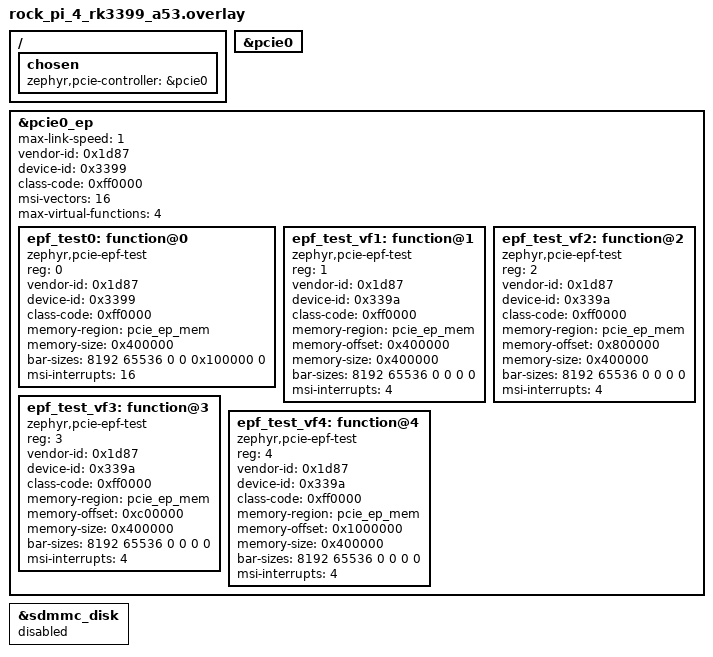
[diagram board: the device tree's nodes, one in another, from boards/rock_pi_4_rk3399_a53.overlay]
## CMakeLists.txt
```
# SPDX-License-Identifier: Apache-2.0

cmake_minimum_required(VERSION 3.20.0)
find_package(Zephyr REQUIRED HINTS $ENV{ZEPHYR_BASE})
project(rk3399_pcie_shell)

target_sources(app PRIVATE src/main.c)
target_sources_ifdef(CONFIG_SAMPLE_INIT_TRACE app PRIVATE src/inittrace.c)
```

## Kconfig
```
# SPDX-License-Identifier: Apache-2.0

config SAMPLE_INIT_TRACE
	bool "Print a marker between init priority bands"
	help
	  printk "init: <level> <priority>" at PRE_KERNEL_2 0 and at a row of
	  POST_KERNEL priorities, so the last marker on the console tells
	  between which driver priorities a boot hangs. Use with
	  -DEXTRA_CONF_FILE=debug.conf (immediate logging).

source "Kconfig.zephyr"
```

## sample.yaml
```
sample:
  name: RK3399 PCIe shell (root complex / endpoint)
tests:
  sample.boards.rockchip.rk3399.pcie_shell:
    platform_allow:
      - rock_pi_4/rk3399/a53
      - rock_pi_4/rk3399/a53/smp
    tags: pcie
    build_only: true
```

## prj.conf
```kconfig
CONFIG_GPIO=y
CONFIG_LOG=y
CONFIG_SHELL=y
CONFIG_KERNEL_SHELL=y
CONFIG_DEVMEM_SHELL=y
CONFIG_REBOOT=y
CONFIG_SHELL_STACK_SIZE=8192

# root complex
CONFIG_PCIE=y
CONFIG_PCIE_CONTROLLER=y
# endpoint
CONFIG_PCIE_ENDPOINT=y
CONFIG_PCIE_EP_LOG_LEVEL_INF=y
CONFIG_CRC=y
CONFIG_TEST_RANDOM_GENERATOR=y

# config space 32 MiB + outbound 32 MiB + BAR carveout, mapped at run time
CONFIG_KERNEL_VM_SIZE=0x10000000
CONFIG_MAX_XLAT_TABLES=64

# eMMC: boot medium and storage (FAT from 16 MiB, mounted at /EMMC: before
# the PCIe role is read); the micro SD slot
# is left to the JTAG breakout: host only, no SD card disk
CONFIG_SDHC=y
CONFIG_SDHC_INIT_PRIORITY=70
CONFIG_DISK_ACCESS=y
CONFIG_MMC_STACK=y
CONFIG_DISK_DRIVER_MMC=y
CONFIG_FILE_SYSTEM=y
# FAT registered before the eMMC mount (76): default 99 is too late
CONFIG_FILE_SYSTEM_INIT_PRIORITY=74
# the disk drivers on top of the SDHC hosts too (default 90)
CONFIG_SD_INIT_PRIORITY=72
CONFIG_FAT_FILESYSTEM_ELM=y
CONFIG_FS_FATFS_LFN=y
# a blank eMMC stays blank: mkfs over the whole disk would cover the boot area
CONFIG_FS_FATFS_MOUNT_MKFS=n
CONFIG_FILE_SYSTEM_SHELL=y
CONFIG_SETTINGS=y
CONFIG_SETTINGS_FILE=y
CONFIG_SETTINGS_FILE_PATH="/EMMC:/settings"
CONFIG_PCIE_ROLE_SETTINGS=y
CONFIG_MAIN_STACK_SIZE=8192

# SPI flash (4A+/4B+/4C): not used for booting; an old image there would
# win over the eMMC (BootROM order), "flash erase" clears it
CONFIG_SPI=y
CONFIG_FLASH=y
CONFIG_FLASH_SHELL=y

# "fwupdate ymodem" over the shell UART (tio ctrl-t y): <img>-rock_pi_4-spi.bin
# into the SPI NOR boot_partition, or on a board without SPI NOR
# <img>-rock_pi_4-boot.bin into the eMMC boot area
CONFIG_FLASH_MAP=y
CONFIG_FWUPDATE=y
CONFIG_FWUPDATE_BOOT_DISK=y

# SR-IOV strap: the core shows its SR-IOV capability (VFs not driven yet)
CONFIG_PCIE_EPC_RK3399_SRIOV=y
```

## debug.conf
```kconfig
# boot debugging: markers between init priorities, logs printed at once
CONFIG_SAMPLE_INIT_TRACE=y
CONFIG_EARLY_CONSOLE=y
CONFIG_LOG_MODE_IMMEDIATE=y
CONFIG_SDHC_LOG_LEVEL_DBG=y
CONFIG_SD_LOG_LEVEL_DBG=y
CONFIG_PCIE_EP_LOG_LEVEL_DBG=y
CONFIG_SPI_LOG_LEVEL_DBG=y
# printk and logs straight to the UART, not through the shell log backend
# (that one only prints once the shell thread runs)
CONFIG_LOG_PRINTK=n
CONFIG_SHELL_LOG_BACKEND=n
CONFIG_LOG_BACKEND_UART=y
```

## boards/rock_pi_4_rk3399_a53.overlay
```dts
/*
 * Copyright (c) 2026 Jiri Kastner
 * SPDX-License-Identifier: Apache-2.0
 *
 * Both roles of the one controller; CONFIG_PCIE_ROLE picks at boot.
 */

/ {
	chosen {
		zephyr,pcie-controller = &pcie0;
	};
};

&pcie0 {
	status = "okay";
};

&pcie0_ep {
	/* Gen2 over the crossover cable drops the data link every few hundred
	 * ms, and every drop resets the configuration space (BARs, VFs) */
	max-link-speed = <1>;
	vendor-id = <0x1d87>;
	device-id = <0x3399>;
	class-code = <0xff0000>;
	msi-vectors = <16>;
	status = "okay";

	epf_test0: function@0 {
		compatible = "zephyr,pcie-epf-test";
		reg = <0>;
		vendor-id = <0x1d87>;
		device-id = <0x3399>;
		class-code = <0xff0000>;
		memory-region = <&pcie_ep_mem>;
		memory-size = <0x400000>;
		/* BAR0 registers, 64-bit BARs need even numbers: 32-bit here */
		bar-sizes = <8192 65536 0 0 0x100000 0>;
		msi-interrupts = <16>;
	};
};

/* SD slot host kept for its JTAG handling (force_jtag), no card disk */
&sdmmc_disk {
	status = "disabled";
};

/*
 * SR-IOV: 4 VFs (routing functions 1..4), each a pcie_epf_test with its own
 * 4 MiB of the carveout. The VF BAR layout is shared, so bar-sizes match;
 * BAR4 is left out so 4 VFs fit a 2 MiB bridge window next to the PF.
 * Host: echo 4 > /sys/bus/pci/devices/<bdf>/sriov_numvfs
 */
&pcie0_ep {
	max-virtual-functions = <4>;

	epf_test_vf1: function@1 {
		compatible = "zephyr,pcie-epf-test";
		reg = <1>;
		vendor-id = <0x1d87>;
		device-id = <0x339a>;
		class-code = <0xff0000>;
		memory-region = <&pcie_ep_mem>;
		memory-offset = <0x400000>;
		memory-size = <0x400000>;
		bar-sizes = <8192 65536 0 0 0 0>;
		msi-interrupts = <4>;
	};

	epf_test_vf2: function@2 {
		compatible = "zephyr,pcie-epf-test";
		reg = <2>;
		vendor-id = <0x1d87>;
		device-id = <0x339a>;
		class-code = <0xff0000>;
		memory-region = <&pcie_ep_mem>;
		memory-offset = <0x800000>;
		memory-size = <0x400000>;
		bar-sizes = <8192 65536 0 0 0 0>;
		msi-interrupts = <4>;
	};

	epf_test_vf3: function@3 {
		compatible = "zephyr,pcie-epf-test";
		reg = <3>;
		vendor-id = <0x1d87>;
		device-id = <0x339a>;
		class-code = <0xff0000>;
		memory-region = <&pcie_ep_mem>;
		memory-offset = <0xc00000>;
		memory-size = <0x400000>;
		bar-sizes = <8192 65536 0 0 0 0>;
		msi-interrupts = <4>;
	};

	epf_test_vf4: function@4 {
		compatible = "zephyr,pcie-epf-test";
		reg = <4>;
		vendor-id = <0x1d87>;
		device-id = <0x339a>;
		class-code = <0xff0000>;
		memory-region = <&pcie_ep_mem>;
		memory-offset = <0x1000000>;
		memory-size = <0x400000>;
		bar-sizes = <8192 65536 0 0 0 0>;
		msi-interrupts = <4>;
	};
};
```

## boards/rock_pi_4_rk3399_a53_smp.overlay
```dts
/*
 * Copyright (c) 2026 Jiri Kastner
 * SPDX-License-Identifier: Apache-2.0
 *
 * Both roles of the one controller; CONFIG_PCIE_ROLE picks at boot.
 */

/ {
	chosen {
		zephyr,pcie-controller = &pcie0;
	};
};

&pcie0 {
	status = "okay";
};

&pcie0_ep {
	vendor-id = <0x1d87>;
	device-id = <0x3399>;
	class-code = <0xff0000>;
	msi-vectors = <16>;
	status = "okay";

	epf_test0: function@0 {
		compatible = "zephyr,pcie-epf-test";
		reg = <0>;
		vendor-id = <0x1d87>;
		device-id = <0x3399>;
		class-code = <0xff0000>;
		memory-region = <&pcie_ep_mem>;
		memory-size = <0x400000>;
		/* BAR0 registers, 64-bit BARs need even numbers: 32-bit here */
		bar-sizes = <8192 65536 0 0 0x100000 0>;
		msi-interrupts = <16>;
	};
};

/* SD slot host kept for its JTAG handling (force_jtag), no card disk */
&sdmmc_disk {
	status = "disabled";
};

/*
 * SR-IOV: 4 VFs (routing functions 1..4), each a pcie_epf_test with its own
 * 4 MiB of the carveout. The VF BAR layout is shared, so bar-sizes match;
 * BAR4 is left out so 4 VFs fit a 2 MiB bridge window next to the PF.
 * Host: echo 4 > /sys/bus/pci/devices/<bdf>/sriov_numvfs
 */
&pcie0_ep {
	max-virtual-functions = <4>;

	epf_test_vf1: function@1 {
		compatible = "zephyr,pcie-epf-test";
		reg = <1>;
		vendor-id = <0x1d87>;
		device-id = <0x339a>;
		class-code = <0xff0000>;
		memory-region = <&pcie_ep_mem>;
		memory-offset = <0x400000>;
		memory-size = <0x400000>;
		bar-sizes = <8192 65536 0 0 0 0>;
		msi-interrupts = <4>;
	};

	epf_test_vf2: function@2 {
		compatible = "zephyr,pcie-epf-test";
		reg = <2>;
		vendor-id = <0x1d87>;
		device-id = <0x339a>;
		class-code = <0xff0000>;
		memory-region = <&pcie_ep_mem>;
		memory-offset = <0x800000>;
		memory-size = <0x400000>;
		bar-sizes = <8192 65536 0 0 0 0>;
		msi-interrupts = <4>;
	};

	epf_test_vf3: function@3 {
		compatible = "zephyr,pcie-epf-test";
		reg = <3>;
		vendor-id = <0x1d87>;
		device-id = <0x339a>;
		class-code = <0xff0000>;
		memory-region = <&pcie_ep_mem>;
		memory-offset = <0xc00000>;
		memory-size = <0x400000>;
		bar-sizes = <8192 65536 0 0 0 0>;
		msi-interrupts = <4>;
	};

	epf_test_vf4: function@4 {
		compatible = "zephyr,pcie-epf-test";
		reg = <4>;
		vendor-id = <0x1d87>;
		device-id = <0x339a>;
		class-code = <0xff0000>;
		memory-region = <&pcie_ep_mem>;
		memory-offset = <0x1000000>;
		memory-size = <0x400000>;
		bar-sizes = <8192 65536 0 0 0 0>;
		msi-interrupts = <4>;
	};
};
```

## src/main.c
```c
/*
 * Copyright (c) 2026 Jiri Kastner
 * SPDX-License-Identifier: Apache-2.0
 *
 * RK3399 PCIe in either role, driven from the shell ("pcie ..."). The eMMC
 * is the boot medium and the storage: its FAT partition is mounted at
 * /EMMC: before the PCIe role is read from settings. The micro SD slot is
 * left to the JTAG breakout (no SD card disk); "emmc update <file>" rewrites
 * the eMMC boot area (MBR, idbloader, FIT) from a file, e.g. on /EMMC:.
 * The BootROM tries the SPI NOR first: "fwupdate ymodem" writes
 * <img>-rock_pi_4-spi.bin there over the shell UART, "flash erase" of its
 * first sector falls back to the eMMC.
 */

#include <stdlib.h>
#include <string.h>

#include <ff.h>
#include <zephyr/device.h>
#include <zephyr/drivers/pcie/role.h>
#include <zephyr/fs/fs.h>
#include <zephyr/init.h>
#include <zephyr/kernel.h>
#include <zephyr/shell/shell.h>
#include <zephyr/storage/disk_access.h>
#include <zephyr/sys/printk.h>
#include <zephyr/sys/sys_io.h>

static FATFS fat_emmc;
static struct fs_mount_t emmc_mnt = {
	.type = FS_FATFS,
	.mnt_point = "/EMMC:",
	.fs_data = &fat_emmc,
	/* no mkfs on a blank eMMC: it would cover the boot area at sector 64 */
	.flags = FS_MOUNT_FLAG_NO_FORMAT,
};
static int emmc_mount_ret = -ENODEV;

/* after the SDHC hosts (70), the disks (72) and FAT (74); before the PCIe role (81) */
static int emmc_mount(void)
{
	emmc_mount_ret = fs_mount(&emmc_mnt);
	return 0;
}
SYS_INIT(emmc_mount, POST_KERNEL, 76);

#define SECT    512U
#define CHUNK   (64U * SECT)
static uint8_t buf[CHUNK] __aligned(64);
static uint8_t chk[CHUNK] __aligned(64);

/*
 * Boot area of a raw image (MBR, idbloader at 64, FIT at 2048) from a file
 * to the eMMC from sector 0. The FAT from BOOT_AREA on, where the file may
 * live, is left alone: a full -emmc.bin is cut there.
 */
#define BOOT_AREA (32768U * SECT)
static int cmd_update(const struct shell *sh, size_t argc, char **argv)
{
	struct fs_dirent st;
	struct fs_file_t f;
	uint32_t count = 0, sz = 0;
	size_t done = 0;
	int ret;

	ret = fs_stat(argv[1], &st);
	if (ret != 0) {
		shell_error(sh, "%s: %d", argv[1], ret);
		return ret;
	}
	if (st.size > BOOT_AREA) {
		st.size = BOOT_AREA;
	}
	ret = disk_access_init("EMMC");
	if (ret == 0) {
		ret = disk_access_ioctl("EMMC", DISK_IOCTL_GET_SECTOR_COUNT, &count);
	}
	if (ret == 0) {
		ret = disk_access_ioctl("EMMC", DISK_IOCTL_GET_SECTOR_SIZE, &sz);
	}
	if (ret != 0 || sz != SECT) {
		shell_error(sh, "eMMC not usable (%d, sector %u)", ret, sz);
		return ret ? ret : -EIO;
	}
	if (DIV_ROUND_UP(st.size, SECT) > count) {
		shell_error(sh, "image %zu B > eMMC %u sectors", st.size, count);
		return -EFBIG;
	}
	fs_file_t_init(&f);
	ret = fs_open(&f, argv[1], FS_O_READ);
	if (ret != 0) {
		return ret;
	}
	shell_print(sh, "%s: %zu bytes to the eMMC (%u sectors)", argv[1], st.size, count);
	while (done < st.size) {
		ssize_t n = fs_read(&f, buf, MIN(CHUNK, st.size - done));
		uint32_t sect, ns;

		if (n <= 0) {
			ret = n < 0 ? (int)n : -EIO;
			break;
		}
		memset(buf + n, 0, CHUNK - n);
		sect = done / SECT;
		ns = DIV_ROUND_UP(n, SECT);
		ret = disk_access_write("EMMC", buf, sect, ns);
		if (ret == 0) {
			ret = disk_access_read("EMMC", chk, sect, ns);
		}
		if (ret == 0 && memcmp(buf, chk, ns * SECT) != 0) {
			shell_error(sh, "verify failed at sector %u", sect);
			ret = -EIO;
		}
		if (ret != 0) {
			break;
		}
		done += n;
		if ((done % MB(1)) == 0) {
			shell_fprintf(sh, SHELL_NORMAL, ".");
		}
	}
	fs_close(&f);
	(void)disk_access_ioctl("EMMC", DISK_IOCTL_CTRL_SYNC, NULL);
	shell_print(sh, "\n%s: %zu bytes written and verified%s", ret ? "FAILED" : "done", done,
		    ret ? "" : "; reset to boot it");
	return ret;
}

SHELL_STATIC_SUBCMD_SET_CREATE(sub_emmc,
	SHELL_CMD_ARG(update, NULL,
		      "<file>: write the boot area (first 16 MiB) of a raw image to the "
		      "eMMC and verify (e.g. /EMMC:/154-rock_pi_4-boot.bin)",
		      cmd_update, 2, 0),
	SHELL_SUBCMD_SET_END);
SHELL_CMD_REGISTER(emmc, &sub_emmc, "eMMC install", NULL);

/*
 * The BAR carveout (pcie_ep_mem) is identity mapped by its DT memory
 * attribute, so devmem, which maps again, panics on it: read and write it
 * here through that mapping. Offsets: PF at 0, VF n at n * 4 MiB.
 */
#define EP_MEM_BASE DT_REG_ADDR(DT_NODELABEL(pcie_ep_mem))
#define EP_MEM_SIZE DT_REG_SIZE(DT_NODELABEL(pcie_ep_mem))

static int cmd_epmem(const struct shell *sh, size_t argc, char **argv)
{
	unsigned long off = strtoul(argv[1], NULL, 0);
	unsigned long n = argc > 2 ? strtoul(argv[2], NULL, 0) : 4;

	if (off >= EP_MEM_SIZE || (off & 3U) != 0U) {
		shell_error(sh, "offset 0x%lx: word aligned, below 0x%lx", off,
			    (unsigned long)EP_MEM_SIZE);
		return -EINVAL;
	}
	if (argc > 3) {
		sys_write32((uint32_t)strtoul(argv[3], NULL, 0), EP_MEM_BASE + off);
	}
	for (unsigned long i = 0; i < n && off + i * 4U < EP_MEM_SIZE; i++) {
		if ((i % 4U) == 0U) {
			shell_fprintf(sh, SHELL_NORMAL, "%s%08lx:", i ? "\n" : "", off + i * 4U);
		}
		shell_fprintf(sh, SHELL_NORMAL, " %08x", sys_read32(EP_MEM_BASE + off + i * 4U));
	}
	shell_print(sh, "");
	return 0;
}
#ifdef CONFIG_RK3399_NOC_ERRLOG
#include <rk3399_noc.h>
#include <zephyr/fatal.h>
#include <zephyr/logging/log_ctrl.h>

/* show what the interconnect logged (SErrors through the PCIe window) */
void k_sys_fatal_error_handler(unsigned int reason, const struct arch_esf *esf)
{
	ARG_UNUSED(esf);
	LOG_PANIC();
	rk3399_noc_errlog_dump();
	printk("Halting system (reason %u)\n", reason);
	(void)arch_irq_lock();
	for (;;) {
	}
}
#endif

SHELL_CMD_ARG_REGISTER(epmem, NULL,
		       "<offset> [words] [value]: BAR carveout (PF 0, VF n at n*4M); value writes "
		       "the first word",
		       cmd_epmem, 2, 2);

int main(void)
{
	enum pcie_role saved;
	bool have = pcie_role_saved(&saved);

	printk("eMMC: %s (%d)\n", emmc_mount_ret == 0 ? "mounted at /EMMC:" : "no FAT",
	       emmc_mount_ret);
	printk("RK3399 PCIe %s (saved: %s, in %s); \"pcie controller mode rc|ep\", "
	       "then a warm reset (\"kernel reboot warm\")\n",
	       pcie_role_get() == PCIE_ROLE_RC ? "root complex" : "endpoint",
	       have ? (saved == PCIE_ROLE_RC ? "rc" : "ep") : "-", pcie_role_storage());
	return 0;
}
```

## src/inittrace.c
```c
/*
 * Copyright (c) 2026 Jiri Kastner
 * SPDX-License-Identifier: Apache-2.0
 *
 * Markers between init priorities (CONFIG_SAMPLE_INIT_TRACE): the last
 * one printed brackets the device whose init does not return.
 * RK3399 drivers here: reset 35, GPIO 40, syscon 50, SDHC 70 (eMMC, SD),
 * SPI/SPI NOR 70/80, eMMC mount 76, role 81, EPC 82, EPF 83, RC 84.
 */

#include <zephyr/init.h>
#include <zephyr/sys/printk.h>
#include <zephyr/arch/cpu.h>
#include <zephyr/sys/sys_io.h>

/*
 * With CONFIG_RK3399_EARLY_MARKS the marker also goes straight to UART2
 * (identity mapped then), so it shows even when printk output is held back
 * (shell log backend not started yet) or the console driver misbehaves.
 */
static void raw(const char *s)
{
#if defined(CONFIG_RK3399_EARLY_MARKS)
	for (; *s != '\0'; s++) {
		while ((sys_read32(0xff1a0014UL) & 0x20U) == 0U) {
		}
		sys_write32((uint32_t)*s, 0xff1a0000UL);
	}
#else
	ARG_UNUSED(s);
#endif
}

#define MARK(level, prio)                                                                          \
	static int mark_##level##_##prio(void)                                                     \
	{                                                                                          \
		raw("\r\n[raw] init: " #level " " #prio "\r\n");                                    \
		printk("init: " #level " " #prio "\n");                                            \
		return 0;                                                                          \
	}                                                                                          \
	SYS_INIT(mark_##level##_##prio, level, prio)

MARK(PRE_KERNEL_2, 0);
MARK(POST_KERNEL, 0);
MARK(POST_KERNEL, 36);
MARK(POST_KERNEL, 41);
MARK(POST_KERNEL, 51);
MARK(POST_KERNEL, 69);
MARK(POST_KERNEL, 71);
MARK(POST_KERNEL, 75);
MARK(POST_KERNEL, 77);
MARK(POST_KERNEL, 80);
MARK(POST_KERNEL, 82);
MARK(POST_KERNEL, 83);
MARK(POST_KERNEL, 84);
MARK(POST_KERNEL, 85);
MARK(POST_KERNEL, 99);
MARK(APPLICATION, 0);
```
